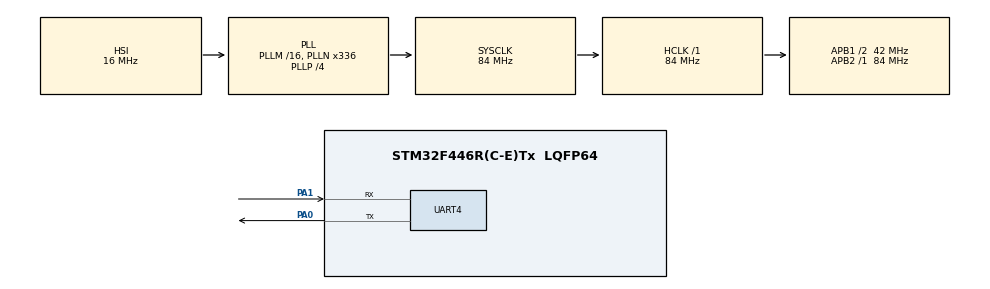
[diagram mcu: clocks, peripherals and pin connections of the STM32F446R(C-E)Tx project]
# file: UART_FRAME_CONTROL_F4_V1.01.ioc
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Dma.Request0=UART4_RX
Dma.Request1=UART4_TX
Dma.UART4_RX.0.Direction=DMA_PERIPH_TO_MEMORY
Dma.UART4_RX.0.FIFOMode=DMA_FIFOMODE_DISABLE
Dma.UART4_RX.0.Instance=DMA1_Stream2
Dma.UART4_RX.0.MemDataAlignment=DMA_MDATAALIGN_BYTE
Dma.UART4_RX.0.MemInc=DMA_MINC_ENABLE
Dma.UART4_RX.0.Mode=DMA_CIRCULAR
Dma.UART4_RX.0.PeriphDataAlignment=DMA_PDATAALIGN_BYTE
Dma.UART4_RX.0.PeriphInc=DMA_PINC_DISABLE
Dma.UART4_RX.0.Priority=DMA_PRIORITY_LOW
Dma.UART4_TX.1.Direction=DMA_MEMORY_TO_PERIPH
Dma.UART4_TX.1.FIFOMode=DMA_FIFOMODE_DISABLE
Dma.UART4_TX.1.Instance=DMA1_Stream4
Dma.UART4_TX.1.MemDataAlignment=DMA_MDATAALIGN_BYTE
Dma.UART4_TX.1.MemInc=DMA_MINC_ENABLE
Dma.UART4_TX.1.Mode=DMA_CIRCULAR
Dma.UART4_TX.1.PeriphDataAlignment=DMA_PDATAALIGN_BYTE
Dma.UART4_TX.1.PeriphInc=DMA_PINC_DISABLE
Dma.UART4_TX.1.Priority=DMA_PRIORITY_LOW
Mcu.Family=STM32F4
Mcu.Name=STM32F446R(C-E)Tx
Mcu.Package=LQFP64
NVIC.DMA1_Stream2_IRQn=true\:0\:0\:false\:false\:true\:false\:true\:true
NVIC.DMA1_Stream4_IRQn=true\:0\:0\:false\:false\:true\:false\:true\:true
NVIC.PriorityGroup=NVIC_PRIORITYGROUP_0
NVIC.UART4_IRQn=true\:0\:0\:false\:false\:true\:true\:true\:true
PA0-WKUP.Mode=Asynchronous
PA0-WKUP.Signal=UART4_TX
PA1.Mode=Asynchronous
PA1.Signal=UART4_RX
ProjectManager.HeapSize=0x200
ProjectManager.StackSize=0x400
ProjectManager.TargetToolchain=STM32CubeIDE
RCC.AHBFreq_Value=84000000
RCC.APB1CLKDivider=RCC_HCLK_DIV2
RCC.APB1Freq_Value=42000000
RCC.APB1TimFreq_Value=84000000
RCC.APB2Freq_Value=84000000
RCC.APB2TimFreq_Value=84000000
RCC.CortexFreq_Value=84000000
RCC.FLatency-AdvancedSettings=FLASH_LATENCY_2
RCC.HCLKFreq_Value=84000000
RCC.HSE_VALUE=8000000
RCC.HSI_VALUE=16000000
RCC.LSE_VALUE=32768
RCC.PLLN=336
RCC.PLLP=RCC_PLLP_DIV4
RCC.SYSCLKFreq_VALUE=84000000
RCC.SYSCLKSource=RCC_SYSCLKSOURCE_PLLCLK
RCC.USBFreq_Value=168000000
RCC.VCOOutputFreq_Value=336000000
UART4.VirtualMode=Asynchronous
board=NUCLEO-F446RE

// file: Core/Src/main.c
/* USER CODE BEGIN Header */
/**
  ******************************************************************************
  * @file           : main.c
  * @brief          : Main program body
  ******************************************************************************
  * @attention
  *
  * Copyright (c) 2024 STMicroelectronics.
  * All rights reserved.
  *
  * This software is licensed under terms that can be found in the LICENSE file
  * in the root directory of this software component.
  * If no LICENSE file comes with this software, it is provided AS-IS.
  *
  ******************************************************************************
  */
/* USER CODE END Header */
#include "main.h"
#include <string.h>
#include <stdlib.h>
#include <stdio.h>
#include <stdint.h>

UART_HandleTypeDef huart4;
DMA_HandleTypeDef hdma_uart4_rx;
DMA_HandleTypeDef hdma_uart4_tx;

void SystemClock_Config(void);
static void MX_GPIO_Init(void);
static void MX_DMA_Init(void);
static void MX_UART4_Init(void);

/* USER CODE BEGIN 0 */

#define BUFFER_SIZE 256

#define HEADER1 ':'
#define HEADER2 'A'
#define HEADER3 '4'
#define HEADER4 '2'
#define HEADER5 '*'
#define TRAILER ';'

uint8_t rxBuffer[BUFFER_SIZE];
uint8_t circularBuffer[BUFFER_SIZE];
uint16_t writeIndex = 0;
uint8_t dataSizeStr[BUFFER_SIZE] = {0};
uint8_t dataBuffer[BUFFER_SIZE] = {0};
uint8_t dataSizeIndex = 0;
uint16_t dataIndex = 0;

int dataSize = 0;
int uart_data_index = 0;
int ham_data = 0;

uint8_t calculatedCRC = 0;
uint8_t receivedCRC = 0;
uint8_t validPacket = 1;

uint8_t CalculateCRC( uint8_t *data, uint16_t length) {

    uint8_t crc = 0;
    for (uint16_t i = 0; i < length; i++) {
        crc ^= data[i];
    }
    return crc;
}

void ProcessData(void) {

	for (int i = 0; i < BUFFER_SIZE; i++) {
		// Paket başlangıcı aranıyor
		if (circularBuffer[i] == HEADER1
				&& circularBuffer[(i + 1) % BUFFER_SIZE] == HEADER2
				&& circularBuffer[(i + 2) % BUFFER_SIZE] == HEADER3
				&& circularBuffer[(i + 3) % BUFFER_SIZE] == HEADER4
				&& circularBuffer[(i + 4) % BUFFER_SIZE] == HEADER5) {

			// Paket başlangıcı bulundu
			dataIndex = (i + 5) % BUFFER_SIZE;

			memset(dataSizeStr, 0, sizeof(dataSizeStr));
			dataSizeIndex = 0;

			while (circularBuffer[dataIndex] != HEADER5 && dataSizeIndex < 2) {
				dataSizeStr[dataSizeIndex++] = circularBuffer[dataIndex];
				dataIndex = (dataIndex + 1) % BUFFER_SIZE;
			}

			// Yıldız (*) karakteri kontrolü
			if (circularBuffer[dataIndex] != HEADER5) {
				validPacket = 0;
			}

			if (validPacket) {
				dataSizeStr[dataSizeIndex] = '\0';
				dataSize = atoi(dataSizeStr);

				// Veriyi oku
				dataIndex = (dataIndex + 1) % BUFFER_SIZE; // * karakterini atla

				for (uint16_t j = 0; j < dataSize; j++) {

					dataBuffer[j] = circularBuffer[dataIndex];
					dataIndex = (dataIndex + 1) % BUFFER_SIZE;
				}

				if (circularBuffer[dataIndex] != HEADER5) {
					validPacket = 0;
				}

				// CRC'yi oku
				dataIndex = (dataIndex + 1) % BUFFER_SIZE; // * karakterini atla

				receivedCRC = circularBuffer[dataIndex];
				dataIndex = (dataIndex + 1) % BUFFER_SIZE;

				// Sonlandırıcı karakteri kontrol et
				if (circularBuffer[dataIndex] == TRAILER) {
					// CRC'yi hesapla ve kontrol et
					calculatedCRC = CalculateCRC(dataBuffer, dataSize);

					if (calculatedCRC == receivedCRC) {
						// Veri doğru iletilmiş
						ham_data = atoi((char*) dataBuffer);
						validPacket = 1; // Paket geçerli

					}
				} else {
					validPacket = 0;
				}
			}
		}
	}
}

void HAL_UARTEx_RxEventCallback(UART_HandleTypeDef *huart, uint16_t Size) {

    if (huart->Instance == UART4) {
        // Gelen veriyi dönen buffer'a yaz
    	 HAL_UARTEx_ReceiveToIdle_DMA(&huart4, rxBuffer, BUFFER_SIZE);
		for (uint16_t i = 0; i < BUFFER_SIZE; i++) {
			circularBuffer[i] = rxBuffer[i];
			if (writeIndex >= BUFFER_SIZE) {
				writeIndex = 0;
			}
		}

        // Gelen veriyi işle
        ProcessData();
    }
}

/* USER CODE END 0 */

int main(void)
{

  /* MCU Configuration--------------------------------------------------------*/

  /* Reset of all peripherals, Initializes the Flash interface and the Systick. */
  HAL_Init();

  /* Configure the system clock */
  SystemClock_Config();

  /* Initialize all configured peripherals */
  MX_GPIO_Init();
  MX_DMA_Init();
  MX_UART4_Init();
  /* USER CODE BEGIN 2 */
//  HAL_UART_Receive_DMA(&huart4, rxBuffer, 1);
  HAL_UARTEx_ReceiveToIdle_DMA(&huart4, rxBuffer, BUFFER_SIZE);
//  HAL_UART_Transmit_DMA(&huart4, data_2, 10);
  /* USER CODE END 2 */

  /* Infinite loop */
  /* USER CODE BEGIN WHILE */
  while (1)
  {
//	  data_control();
    /* USER CODE END WHILE */

  }
}

void SystemClock_Config(void)
{
  RCC_OscInitTypeDef RCC_OscInitStruct = {0};
  RCC_ClkInitTypeDef RCC_ClkInitStruct = {0};

  /** Configure the main internal regulator output voltage
  */
  __HAL_RCC_PWR_CLK_ENABLE();
  __HAL_PWR_VOLTAGESCALING_CONFIG(PWR_REGULATOR_VOLTAGE_SCALE3);

  /** Initializes the RCC Oscillators according to the specified parameters
  * in the RCC_OscInitTypeDef structure.
  */
  RCC_OscInitStruct.OscillatorType = RCC_OSCILLATORTYPE_HSI;
  RCC_OscInitStruct.HSIState = RCC_HSI_ON;
  RCC_OscInitStruct.HSICalibrationValue = RCC_HSICALIBRATION_DEFAULT;
  RCC_OscInitStruct.PLL.PLLState = RCC_PLL_ON;
  RCC_OscInitStruct.PLL.PLLSource = RCC_PLLSOURCE_HSI;
  RCC_OscInitStruct.PLL.PLLM = 16;
  RCC_OscInitStruct.PLL.PLLN = 336;
  RCC_OscInitStruct.PLL.PLLP = RCC_PLLP_DIV4;
  RCC_OscInitStruct.PLL.PLLQ = 2;
  RCC_OscInitStruct.PLL.PLLR = 2;
  if (HAL_RCC_OscConfig(&RCC_OscInitStruct) != HAL_OK)
  {
    Error_Handler();
  }

  /** Initializes the CPU, AHB and APB buses clocks
  */
  RCC_ClkInitStruct.ClockType = RCC_CLOCKTYPE_HCLK|RCC_CLOCKTYPE_SYSCLK
                              |RCC_CLOCKTYPE_PCLK1|RCC_CLOCKTYPE_PCLK2;
  RCC_ClkInitStruct.SYSCLKSource = RCC_SYSCLKSOURCE_PLLCLK;
  RCC_ClkInitStruct.AHBCLKDivider = RCC_SYSCLK_DIV1;
  RCC_ClkInitStruct.APB1CLKDivider = RCC_HCLK_DIV2;
  RCC_ClkInitStruct.APB2CLKDivider = RCC_HCLK_DIV1;

  if (HAL_RCC_ClockConfig(&RCC_ClkInitStruct, FLASH_LATENCY_2) != HAL_OK)
  {
    Error_Handler();
  }
}

static void MX_UART4_Init(void)
{

  huart4.Instance = UART4;
  huart4.Init.BaudRate = 115200;
  huart4.Init.WordLength = UART_WORDLENGTH_8B;
  huart4.Init.StopBits = UART_STOPBITS_1;
  huart4.Init.Parity = UART_PARITY_NONE;
  huart4.Init.Mode = UART_MODE_TX_RX;
  huart4.Init.HwFlowCtl = UART_HWCONTROL_NONE;
  huart4.Init.OverSampling = UART_OVERSAMPLING_16;
  if (HAL_UART_Init(&huart4) != HAL_OK)
  {
    Error_Handler();
  }

}

static void MX_DMA_Init(void)
{

  /* DMA controller clock enable */
  __HAL_RCC_DMA1_CLK_ENABLE();

  /* DMA interrupt init */
  /* DMA1_Stream2_IRQn interrupt configuration */
  HAL_NVIC_SetPriority(DMA1_Stream2_IRQn, 0, 0);
  HAL_NVIC_EnableIRQ(DMA1_Stream2_IRQn);
  /* DMA1_Stream4_IRQn interrupt configuration */
  HAL_NVIC_SetPriority(DMA1_Stream4_IRQn, 0, 0);
  HAL_NVIC_EnableIRQ(DMA1_Stream4_IRQn);

}

static void MX_GPIO_Init(void)
{

  /* GPIO Ports Clock Enable */
  __HAL_RCC_GPIOA_CLK_ENABLE();

}

void Error_Handler(void)
{
  __disable_irq();
  while (1)
  {
  }
}
